# RTS5921 register map
Vendor: Realtek Semiconductor Corp.; Series: RTS5921 Series; File version: 0.01
CPU: ARMV8MBL r0p0, little endian, MPU, no FPU, VTOR, 3 interrupt priority bits
Registers are 32-bit, read-write, reset 0x0 unless marked. A register's access mark holds for its fields unless they carry their own. Offsets are from the block's base; [hi:lo] are bit positions; {n}, {i} and the like mark numbered series; 'fields as' and 'values as' point back to an identical list.

## USB_IN_EP — USB OTG IN-Endpoint Controller
Base 0x40040900
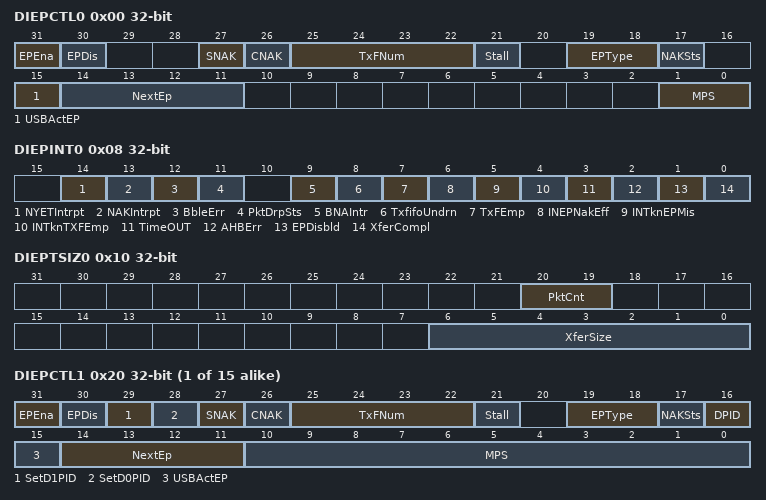
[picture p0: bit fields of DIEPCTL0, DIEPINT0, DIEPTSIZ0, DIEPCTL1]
0x00 DIEPCTL0 — Device Control IN Endpoint 0 Control Register
  [31] EPEna — Endpoint enable
  [30] EPDis — Endpoint disable
  [27] SNAK wo — Set NAK
  [26] CNAK wo — Clear NAK
  [25:22] TxFNum — TxFIFO number
  [21] Stall — Endpoint STALL handshake
  [19:18] EPType ro — Endpoint type
  [17] NAKSts ro — NAK status
  [15] USBActEP ro — USB active endpoint
  [14:11] NextEp — Next endpoint number
  [1:0] MPS — Maximum packet size
    0=BYTES64 (64 bytes); 1=BYTES32 (32 bytes); 2=BYTES16 (16 bytes); 3=BYTES8 (8 bytes)
0x08 DIEPINT0 — Device IN Endpoint 0 Interrupt Register
  [14] NYETIntrpt — NYET interrupt
    0=INACTIVE (No interrupt); 1=ACTIVE (NYET interrupt)
  [13] NAKIntrpt — NAK interrupt
    0=INACTIVE (No interrupt); 1=ACTIVE (NAK interrupt)
  [12] BbleErr — Babble error interrupt
    0=INACTIVE (No interrupt); 1=ACTIVE (Babble error interrupt)
  [11] PktDrpSts — Packet drop status
    0=INACTIVE (No packet dropped); 1=ACTIVE (Packet dropped)
  [9] BNAIntr — BNA (Buffer Not Available) interrupt
    0=INACTIVE (No BNA interrupt); 1=ACTIVE (BNA interrupt)
  [8] TxfifoUndrn — TxFIFO underrun interrupt (IN endpoint only)
    0=INACTIVE (No TxFIFO underrun); 1=ACTIVE (TxFIFO underrun interrupt)
  [7] TxFEmp — Transmit FIFO empty (IN endpoint only)
    0=INACTIVE (No TxFIFO empty); 1=ACTIVE (TxFIFO empty)
  [6] INEPNakEff — IN endpoint NAK effective
    0=INACTIVE (No NAK effective); 1=ACTIVE (NAK effective interrupt)
  [5] INTknEPMis — IN token received with EP mismatch
    0=INACTIVE (No EP mismatch); 1=ACTIVE (EP mismatch interrupt)
  [4] INTknTXFEmp — IN token received when TxFIFO empty
    0=INACTIVE (No TxFIFO empty on IN token); 1=ACTIVE (IN token with TxFIFO empty interrupt)
  [3] TimeOUT — Timeout condition
    0=INACTIVE (No timeout); 1=ACTIVE (Timeout interrupt)
  [2] AHBErr — AHB error interrupt
    0=INACTIVE (No AHB error); 1=ACTIVE (AHB error interrupt)
  [1] EPDisbld — Endpoint disabled interrupt
    0=INACTIVE (No endpoint disabled interrupt); 1=ACTIVE (Endpoint disabled interrupt)
  [0] XferCompl — Transfer completed interrupt
0x10 DIEPTSIZ0 — Device IN Endpoint 0 Transfer Size Register
  [20:19] PktCnt — USB packet count
  [6:0] XferSize — Transfer size in bytes
{0x14+0x20*i} DIEPDMA{i} (i=0..15) — Device IN Endpoint {i} DMA Address Register
{0x18+0x20*i} DTXFSTS{i} ro (i=0..15) — Device IN Endpoint {i} Transmit FIFO Status Register
{0x1C+0x20*i} DIEPDMAB{i} (i=0..15) — Device IN Endpoint {i} Buffer Address Register
{0x0+0x20*i} DIEPCTL{i} (i=1..15) — Device Control IN Endpoint {i} Control Register
  [31] EPEna — Endpoint enable
    0=INACTIVE (No Action); 1=ACTIVE (Enable Endpoint)
  [30] EPDis — Endpoint disable
    0=INACTIVE (No Action); 1=ACTIVE (Disable Endpoint)
  [29] SetD1PID — Set DATA1 PID or set odd (micro)frame
    0=DISABLED (Do not set); 1=ENABLED (Set Endpoint DATA1 PID or Odd Frame)
  [28] SetD0PID — Set DATA0 PID or set even (micro)frame
    0=DISABLED (Do not set); 1=ENABLED (Set Endpoint DATA0 PID or Even Frame)
  [27] SNAK — Set NAK
    0=INACTIVE (No Set NAK); 1=ACTIVE (Set NAK)
  [26] CNAK — Clear NAK
    0=INACTIVE (No Clear NAK); 1=ACTIVE (Clear NAK)
  [25:22] TxFNum — TxFIFO number (IN endpoint only)
    {v}=TXFIFO{v} (v=0..15)
  [21] Stall — STALL handshake
    0=INACTIVE (All non-active tokens); 1=ACTIVE (STALL all active tokens)
  [19:18] EPType — Endpoint type
    0=CONTROL; 1=ISOCHRONOUS; 2=BULK; 3=INTERRUPT
  [17] NAKSts — NAK status
    0=NONNAK (Transmit non-NAK handshakes); 1=NAK (Transmit NAK handshakes)
  [16] DPID — Data PID or even/odd microframe
    0=DATA0EVENFRM (DATA0 or Even Frame); 1=DATA1ODDFRM (DATA1 or Odd Frame)
  [15] USBActEP — USB active endpoint
    0=DISABLED (Not active); 1=ENABLED (Active)
  [14:11] NextEp — Next endpoint
    {v}=EP{v} (v=0..15)
  [10:0] MPS — Maximum packet size in bytes
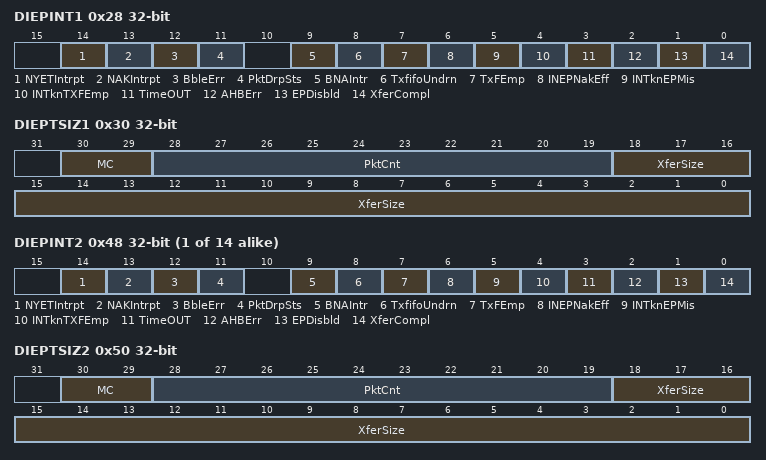
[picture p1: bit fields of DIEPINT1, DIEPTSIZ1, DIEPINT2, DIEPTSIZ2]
0x28 DIEPINT1 — Device IN Endpoint 1 Interrupt Register
  [14] NYETIntrpt — NYET interrupt
  [13] NAKIntrpt — NAK interrupt
  [12] BbleErr — Babble error interrupt
  [11] PktDrpSts — ISOC OUT packet dropped
  [9] BNAIntr — Buffer not available interrupt
  [8] TxfifoUndrn — Tx FIFO underrun interrupt
  [7] TxFEmp ro — Transmit FIFO empty interrupt
  [6] INEPNakEff — IN endpoint NAK effective interrupt
  [5] INTknEPMis — IN token received with EP mismatch
  [4] INTknTXFEmp — IN token received when TxFIFO empty
  [3] TimeOUT — Timeout condition interrupt
  [2] AHBErr — AHB error interrupt
  [1] EPDisbld — Endpoint disabled interrupt
  [0] XferCompl — Transfer completed interrupt
0x30 DIEPTSIZ1 — Device IN Endpoint 1 Transfer Size Register
  [30:29] MC — Packets per microframe for IN endpoint
    1=PACKETONE (1 packet); 2=PACKETTWO (2 packets); 3=PACKETTHREE (3 packets)
  [28:19] PktCnt — USB packet count
  [18:0] XferSize — Transfer size in bytes
{0x8+0x20*i} DIEPINT{i} (i=2..15) — Device Control IN Endpoint {i} Control Register
  fields as DIEPINT1
0x50 DIEPTSIZ2 — Device IN Endpoint 2 Transfer Size Register
  fields as DIEPTSIZ1
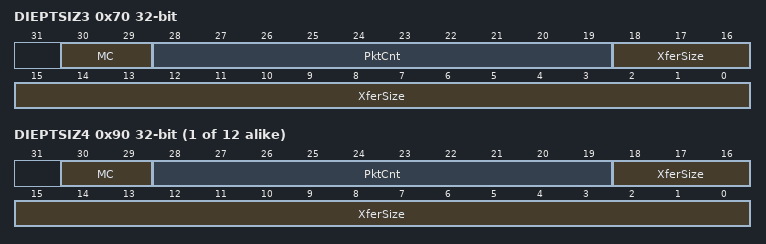
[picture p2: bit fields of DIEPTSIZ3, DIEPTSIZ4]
0x70 DIEPTSIZ3 — Device IN Endpoint 2 Transfer Size Register
  fields as DIEPTSIZ1
{0x10+0x20*i} DIEPTSIZ{i} (i=4..15) — Device IN Endpoint {i} Transfer Size Register
  fields as DIEPTSIZ1
